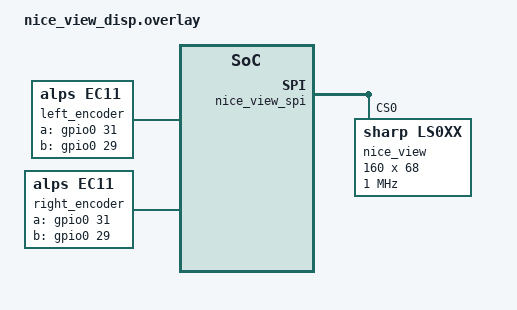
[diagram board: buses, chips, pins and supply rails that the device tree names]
/*
 * Copyright (c) 2022 The ZMK Contributors
 *
 * SPDX-License-Identifier: MIT
 */

&nice_view_spi {
    status = "okay";
    nice_view: ls0xx@0 {
        compatible = "sharp,ls0xx";
        spi-max-frequency = <1000000>;
        reg = <0>;
        width = <160>;
        height = <68>;
    };
};

/ {
    chosen {
        zephyr,display = &nice_view;
    };

    // --- KORRIGIERTE ENCODER DEFINITION ---
    left_encoder: encoder_left {
        compatible = "alps,ec11";
        // Wir nutzen GPIO 0 Pin 31 und GPIO 0 Pin 29 (entspricht oft 21/20 beim Pro Micro)
        a-gpios = <&gpio0 31 (GPIO_ACTIVE_HIGH | GPIO_PULL_UP)>;
        b-gpios = <&gpio0 29 (GPIO_ACTIVE_HIGH | GPIO_PULL_UP)>;
        steps = <80>;
        status = "okay";
    };

    right_encoder: encoder_right {
        compatible = "alps,ec11";
        a-gpios = <&gpio0 31 (GPIO_ACTIVE_HIGH | GPIO_PULL_UP)>;
        b-gpios = <&gpio0 29 (GPIO_ACTIVE_HIGH | GPIO_PULL_UP)>;
        steps = <80>;
        status = "okay";
    };

    sensors: sensors {
        compatible = "zmk,keymap-sensors";
        sensors = <&left_encoder &right_encoder>;
        triggers-per-rotation = <20>;
    };
};
